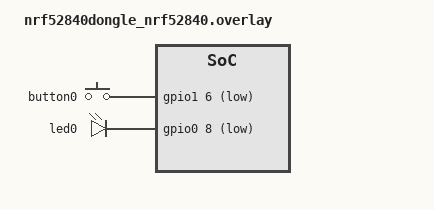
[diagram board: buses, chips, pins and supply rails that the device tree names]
/ {
    aliases {
        sw0 = &button0;
        led0 = &led0;
    };

    buttons {
        compatible = "gpio-keys";
        button0: button_0 {
            gpios = <&gpio1 6 (GPIO_PULL_UP | GPIO_ACTIVE_LOW)>;
        };
    };

    leds {
        compatible = "gpio-leds";
        led0: led_0 {
            gpios = <&gpio0 8 GPIO_ACTIVE_LOW>;
        };
    };
};
